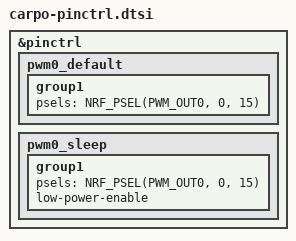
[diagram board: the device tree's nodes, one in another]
/*
*
* Copyright (c) 2024 The ZMK Contributors
* SPDX-License-Identifier: MIT
*
*/

&pinctrl {
    pwm0_default: pwm0_default {
        group1 {
            psels = <NRF_PSEL(PWM_OUT0, 0, 15)>;
        };
    };
    pwm0_sleep: pwm0_sleep {
        group1 {
            psels = <NRF_PSEL(PWM_OUT0, 0, 15)>;
            low-power-enable;
        };
    };
};
